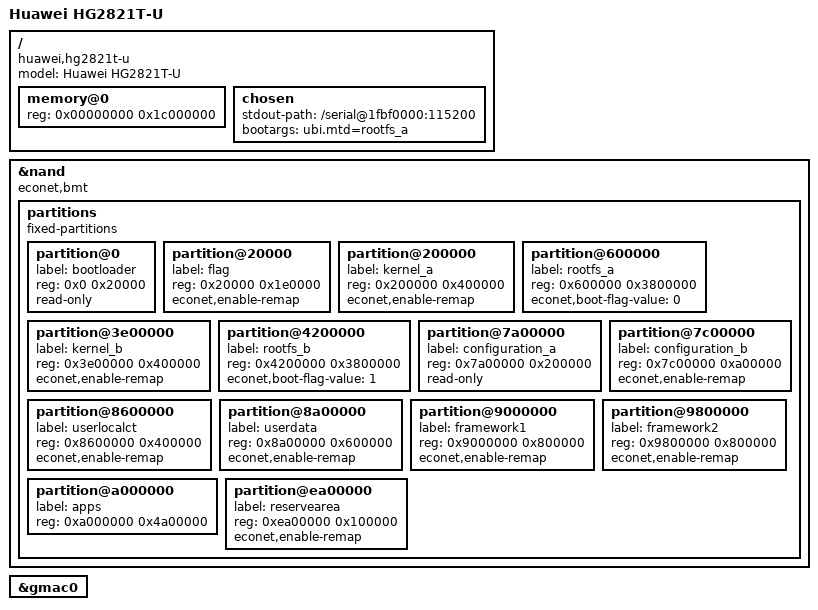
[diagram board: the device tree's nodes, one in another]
// SPDX-License-Identifier: (GPL-2.0-only OR BSD-2-Clause)
/dts-v1/;

#include "en751221.dtsi"

/ {
	model = "Huawei HG2821T-U";
	compatible = "huawei,hg2821t-u", "econet,en751221";

	memory@0 {
		device_type = "memory";
		reg = <0x00000000 0x1c000000>;
	};

	chosen {
		stdout-path = "/serial@1fbf0000:115200";
		bootargs = "ubi.mtd=rootfs_a";
	};
};

&nand {
	status = "okay";
	econet,bmt;

	partitions {
		compatible = "fixed-partitions";
		#address-cells = <1>;
		#size-cells = <1>;

		partition@0 {
			label = "bootloader";
			reg = <0x0 0x20000>;
			read-only;
		};

		partition@20000 {
			label = "flag";
			reg = <0x20000 0x1e0000>;
			econet,enable-remap;
		};

		partition@200000 {
			label = "kernel_a";
			reg = <0x200000 0x400000>;
			econet,enable-remap;
		};

		partition@600000 {
			label = "rootfs_a";
			reg = <0x600000 0x3800000>;
			econet,boot-flag-value = <0>;
		};

		partition@3e00000 {
			label = "kernel_b";
			reg = <0x3e00000 0x400000>;
			econet,enable-remap;
		};

		partition@4200000 {
			label = "rootfs_b";
			reg = <0x4200000 0x3800000>;
			econet,boot-flag-value = <1>;
		};

		partition@7a00000 {
			label = "configuration_a";
			reg = <0x7a00000 0x200000>;
			read-only;
		};

		partition@7c00000 {
			label = "configuration_b";
			reg = <0x7c00000 0xa00000>;
			econet,enable-remap;
		};

		partition@8600000 {
			label = "userlocalct";
			reg = <0x8600000 0x400000>;
			econet,enable-remap;
		};

		partition@8a00000 {
			label = "userdata";
			reg = <0x8a00000 0x600000>;
			econet,enable-remap;
		};

		partition@9000000 {
			label = "framework1";
			reg = <0x9000000 0x800000>;
			econet,enable-remap;
		};

		partition@9800000 {
			label = "framework2";
			reg = <0x9800000 0x800000>;
			econet,enable-remap;
		};

		/* UBI */
		partition@a000000 {
			label = "apps";
			reg = <0xa000000 0x4a00000>;
		};

		partition@ea00000 {
			label = "reservearea";
			reg = <0xea00000 0x100000>;
			econet,enable-remap;
		};
	};
};

&gmac0 {
	status = "okay";
};
